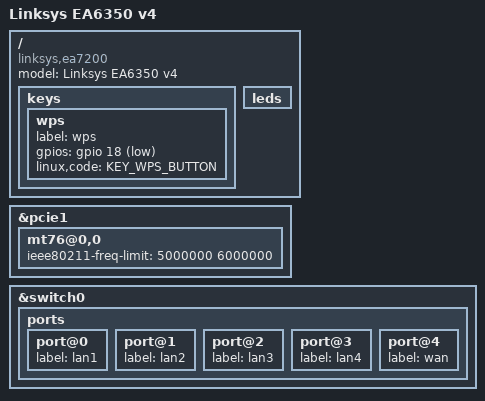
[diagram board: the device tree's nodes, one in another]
// SPDX-License-Identifier: GPL-2.0-or-later OR MIT

#include "mt7621_linksys_ea7xxx.dtsi"

/ {
	compatible = "linksys,ea7200", "mediatek,mt7621-soc";
	model = "Linksys EA6350 v4";

	keys {
		/delete-node/ wps;

		wps {
			label = "wps";
			gpios = <&gpio 18 GPIO_ACTIVE_LOW>;
			linux,code = <KEY_WPS_BUTTON>;
		};
	};

	leds {
		/delete-node/ wan_green;
		/delete-node/ lan1_green;
		/delete-node/ lan2_green;
		/delete-node/ lan3_green;
		/delete-node/ lan4_green;
		/delete-node/ wps;
	};
};

&pcie1 {
	mt76@0,0 {
		ieee80211-freq-limit = <5000000 6000000>;
	};
};

&switch0 {
	ports {
		port@0 {
			label = "lan1";
		};

		port@1 {
			label = "lan2";
		};

		port@2 {
			label = "lan3";
		};

		port@3 {
			label = "lan4";
		};

		port@4 {
			label = "wan";
		};
	};
};
